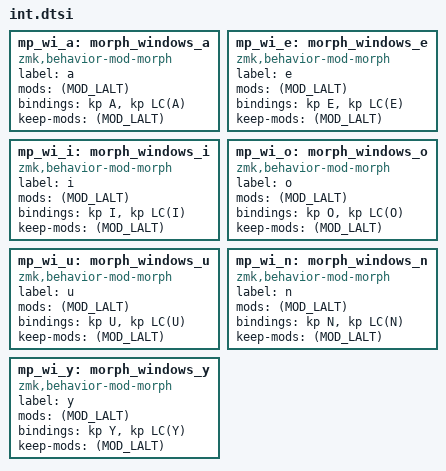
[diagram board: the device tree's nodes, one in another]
mp_wi_a: morph_windows_a {
    compatible = "zmk,behavior-mod-morph";
    label = "a";
    #binding-cells = <0>;
    mods = <(MOD_LALT)>;
    bindings = <&kp A>, <&kp LC(A)>;
    keep-mods = <(MOD_LALT)>;
};

mp_wi_e: morph_windows_e {
    compatible = "zmk,behavior-mod-morph";
    label = "e";
    #binding-cells = <0>;
    mods = <(MOD_LALT)>;
    bindings = <&kp E>, <&kp LC(E)>;
    keep-mods = <(MOD_LALT)>;
};

mp_wi_i: morph_windows_i {
    compatible = "zmk,behavior-mod-morph";
    label = "i";
    #binding-cells = <0>;
    mods = <(MOD_LALT)>;
    bindings = <&kp I>, <&kp LC(I)>;
    keep-mods = <(MOD_LALT)>;
};

mp_wi_o: morph_windows_o {
    compatible = "zmk,behavior-mod-morph";
    label = "o";
    #binding-cells = <0>;
    mods = <(MOD_LALT)>;
    bindings = <&kp O>, <&kp LC(O)>;
    keep-mods = <(MOD_LALT)>;
};

mp_wi_u: morph_windows_u {
    compatible = "zmk,behavior-mod-morph";
    label = "u";
    #binding-cells = <0>;
    mods = <(MOD_LALT)>;
    bindings = <&kp U>, <&kp LC(U)>;
    keep-mods = <(MOD_LALT)>;
};

mp_wi_n: morph_windows_n {
    compatible = "zmk,behavior-mod-morph";
    label = "n";
    #binding-cells = <0>;
    mods = <(MOD_LALT)>;
    bindings = <&kp N>, <&kp LC(N)>;
    keep-mods = <(MOD_LALT)>;
};

mp_wi_y: morph_windows_y {
    compatible = "zmk,behavior-mod-morph";
    label = "y";
    #binding-cells = <0>;
    mods = <(MOD_LALT)>;
    bindings = <&kp Y>, <&kp LC(Y)>;
    keep-mods = <(MOD_LALT)>;
};
